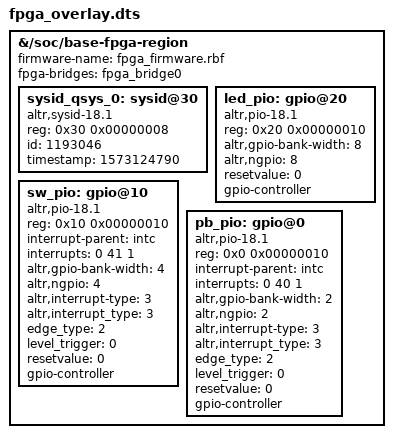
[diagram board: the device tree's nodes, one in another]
/dts-v1/;
/plugin/;
/ {
	fragment@0 {
  		target-path = "/soc/base-fpga-region";
  		#address-cells = <1>;
  		#size-cells = <1>;
  		__overlay__ {
                        #address-cells = <1>;
			#size-cells = <1>;

			firmware-name = "fpga_firmware.rbf";

                        fpga-bridges = <&fpga_bridge0>;

			ranges = <0x00000030 0xff200030 0x00000008>,
				  <0x00000020 0xff200020 0x00000010>,
				  <0x00000010 0xff200010 0x00000010>,
				  <0x00000000 0xff200000 0x00000010>;

			sysid_qsys_0: sysid@30 {
				compatible = "altr,sysid-18.1", "altr,sysid-1.0";
				reg = <0x30 0x00000008>;
				id = <1193046>;
                                timestamp = <1573124790>;	
			}; 

			led_pio: gpio@20 {
				compatible = "altr,pio-18.1", "altr,pio-1.0";
				reg = <0x20 0x00000010>;
				altr,gpio-bank-width = <8>;
                                altr,ngpio = <8>;
				resetvalue = <0>;
                                #gpio-cells = <2>;
				gpio-controller;
			}; 

			sw_pio: gpio@10 {
				compatible = "altr,pio-18.1", "altr,pio-1.0";
				reg = <0x10 0x00000010>;
				interrupt-parent = <&intc>;
				interrupts = <0 41 1>;
				altr,gpio-bank-width = <4>;
                                altr,ngpio = <4>;
				altr,interrupt-type = <3>;
				altr,interrupt_type = <3>;
				edge_type = <2>;
				level_trigger = <0>;
				resetvalue = <0>;
				#gpio-cells = <2>;
				gpio-controller;
			}; 

			pb_pio: gpio@0 {
				compatible = "altr,pio-18.1", "altr,pio-1.0";
				reg = <0x0 0x00000010>;
				interrupt-parent = <&intc>;
				interrupts = <0 40 1>;
				altr,gpio-bank-width = <2>;
                                altr,ngpio = <2>;
				altr,interrupt-type = <3>;
				altr,interrupt_type = <3>;
				edge_type = <2>;
				level_trigger = <0>;
				resetvalue = <0>;
				#gpio-cells = <2>;
				gpio-controller;
			}; 
		};
	};
};
